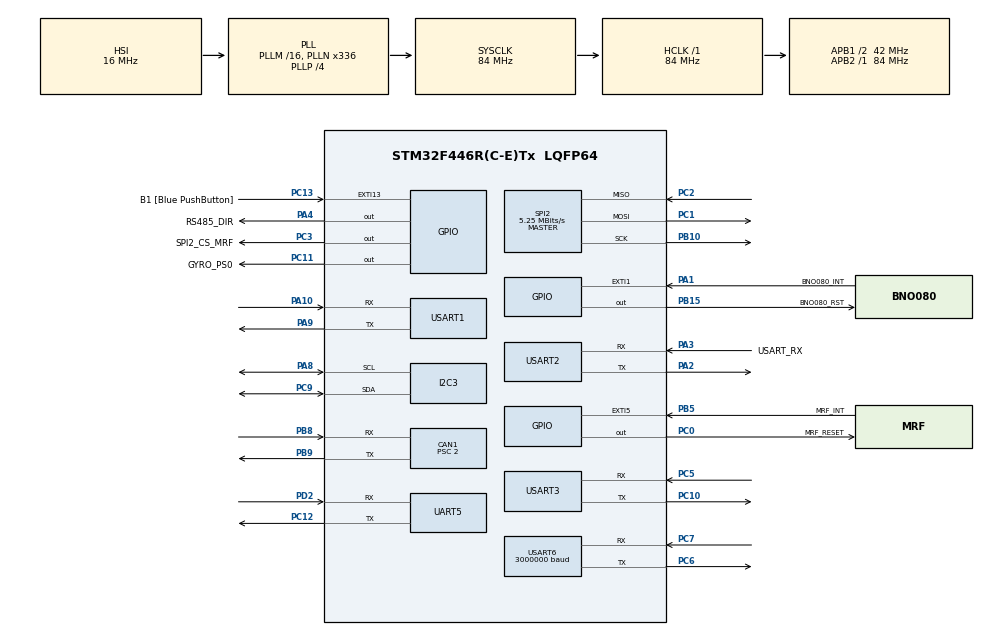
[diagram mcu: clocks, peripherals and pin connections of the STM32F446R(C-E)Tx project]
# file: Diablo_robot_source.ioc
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CAN1.BS1=CAN_BS1_12TQ
CAN1.BS2=CAN_BS2_8TQ
CAN1.CalculateBaudRate=1000000
CAN1.CalculateTimeBit=1000
CAN1.CalculateTimeQuantum=47.61904761904762
CAN1.Prescaler=2
CAN1.SJW=CAN_SJW_1TQ
Dma.Request0=UART5_RX
Dma.Request1=UART5_TX
Dma.Request2=USART1_RX
Dma.Request3=USART1_TX
Dma.Request4=USART3_TX
Dma.Request5=USART2_RX
Dma.Request6=USART2_TX
Dma.UART5_RX.0.Direction=DMA_PERIPH_TO_MEMORY
Dma.UART5_RX.0.FIFOMode=DMA_FIFOMODE_DISABLE
Dma.UART5_RX.0.Instance=DMA1_Stream0
Dma.UART5_RX.0.MemDataAlignment=DMA_MDATAALIGN_BYTE
Dma.UART5_RX.0.MemInc=DMA_MINC_ENABLE
Dma.UART5_RX.0.Mode=DMA_CIRCULAR
Dma.UART5_RX.0.PeriphDataAlignment=DMA_PDATAALIGN_BYTE
Dma.UART5_RX.0.PeriphInc=DMA_PINC_DISABLE
Dma.UART5_RX.0.Priority=DMA_PRIORITY_LOW
Dma.UART5_TX.1.Direction=DMA_MEMORY_TO_PERIPH
Dma.UART5_TX.1.FIFOMode=DMA_FIFOMODE_DISABLE
Dma.UART5_TX.1.Instance=DMA1_Stream7
Dma.UART5_TX.1.MemDataAlignment=DMA_MDATAALIGN_BYTE
Dma.UART5_TX.1.MemInc=DMA_MINC_ENABLE
Dma.UART5_TX.1.Mode=DMA_NORMAL
Dma.UART5_TX.1.PeriphDataAlignment=DMA_PDATAALIGN_BYTE
Dma.UART5_TX.1.PeriphInc=DMA_PINC_DISABLE
Dma.UART5_TX.1.Priority=DMA_PRIORITY_LOW
Dma.USART1_RX.2.Direction=DMA_PERIPH_TO_MEMORY
Dma.USART1_RX.2.FIFOMode=DMA_FIFOMODE_DISABLE
Dma.USART1_RX.2.Instance=DMA2_Stream2
Dma.USART1_RX.2.MemDataAlignment=DMA_MDATAALIGN_BYTE
Dma.USART1_RX.2.MemInc=DMA_MINC_ENABLE
Dma.USART1_RX.2.Mode=DMA_CIRCULAR
Dma.USART1_RX.2.PeriphDataAlignment=DMA_PDATAALIGN_BYTE
Dma.USART1_RX.2.PeriphInc=DMA_PINC_DISABLE
Dma.USART1_RX.2.Priority=DMA_PRIORITY_LOW
Dma.USART1_TX.3.Direction=DMA_MEMORY_TO_PERIPH
Dma.USART1_TX.3.FIFOMode=DMA_FIFOMODE_DISABLE
Dma.USART1_TX.3.Instance=DMA2_Stream7
Dma.USART1_TX.3.MemDataAlignment=DMA_MDATAALIGN_BYTE
Dma.USART1_TX.3.MemInc=DMA_MINC_ENABLE
Dma.USART1_TX.3.Mode=DMA_NORMAL
Dma.USART1_TX.3.PeriphDataAlignment=DMA_PDATAALIGN_BYTE
Dma.USART1_TX.3.PeriphInc=DMA_PINC_DISABLE
Dma.USART1_TX.3.Priority=DMA_PRIORITY_LOW
Dma.USART2_RX.5.Direction=DMA_PERIPH_TO_MEMORY
Dma.USART2_RX.5.FIFOMode=DMA_FIFOMODE_DISABLE
Dma.USART2_RX.5.Instance=DMA1_Stream5
Dma.USART2_RX.5.MemDataAlignment=DMA_MDATAALIGN_BYTE
Dma.USART2_RX.5.MemInc=DMA_MINC_ENABLE
Dma.USART2_RX.5.Mode=DMA_NORMAL
Dma.USART2_RX.5.PeriphDataAlignment=DMA_PDATAALIGN_BYTE
Dma.USART2_RX.5.PeriphInc=DMA_PINC_DISABLE
Dma.USART2_RX.5.Priority=DMA_PRIORITY_LOW
Dma.USART2_TX.6.Direction=DMA_MEMORY_TO_PERIPH
Dma.USART2_TX.6.FIFOMode=DMA_FIFOMODE_DISABLE
Dma.USART2_TX.6.Instance=DMA1_Stream6
Dma.USART2_TX.6.MemDataAlignment=DMA_MDATAALIGN_BYTE
Dma.USART2_TX.6.MemInc=DMA_MINC_ENABLE
Dma.USART2_TX.6.Mode=DMA_NORMAL
Dma.USART2_TX.6.PeriphDataAlignment=DMA_PDATAALIGN_BYTE
Dma.USART2_TX.6.PeriphInc=DMA_PINC_DISABLE
Dma.USART2_TX.6.Priority=DMA_PRIORITY_LOW
Dma.USART3_TX.4.Direction=DMA_MEMORY_TO_PERIPH
Dma.USART3_TX.4.FIFOMode=DMA_FIFOMODE_DISABLE
Dma.USART3_TX.4.Instance=DMA1_Stream3
Dma.USART3_TX.4.MemDataAlignment=DMA_MDATAALIGN_BYTE
Dma.USART3_TX.4.MemInc=DMA_MINC_ENABLE
Dma.USART3_TX.4.Mode=DMA_NORMAL
Dma.USART3_TX.4.PeriphDataAlignment=DMA_PDATAALIGN_BYTE
Dma.USART3_TX.4.PeriphInc=DMA_PINC_DISABLE
Dma.USART3_TX.4.Priority=DMA_PRIORITY_LOW
I2C3.I2C_Mode=I2C_Fast
Mcu.Family=STM32F4
Mcu.Name=STM32F446R(C-E)Tx
Mcu.Package=LQFP64
NVIC.CAN1_RX0_IRQn=true\:0\:0\:false\:false\:true\:true\:true\:true
NVIC.DMA1_Stream0_IRQn=true\:0\:0\:false\:false\:true\:false\:true\:true
NVIC.DMA1_Stream3_IRQn=true\:0\:0\:false\:false\:true\:false\:true\:true
NVIC.DMA1_Stream5_IRQn=true\:0\:0\:false\:false\:true\:false\:true\:true
NVIC.DMA1_Stream6_IRQn=true\:0\:0\:false\:false\:true\:false\:true\:true
NVIC.DMA1_Stream7_IRQn=true\:0\:0\:false\:false\:true\:false\:true\:true
NVIC.DMA2_Stream2_IRQn=true\:0\:0\:false\:false\:true\:false\:true\:true
NVIC.DMA2_Stream7_IRQn=true\:0\:0\:false\:false\:true\:false\:true\:true
NVIC.EXTI15_10_IRQn=true\:0\:0\:false\:false\:true\:true\:true\:true
NVIC.EXTI1_IRQn=true\:0\:0\:false\:false\:true\:true\:true\:true
NVIC.EXTI9_5_IRQn=true\:0\:0\:false\:false\:true\:true\:true\:true
NVIC.PriorityGroup=NVIC_PRIORITYGROUP_0
NVIC.TIM2_IRQn=true\:0\:0\:false\:false\:true\:true\:true\:true
NVIC.TIM3_IRQn=true\:0\:0\:false\:false\:true\:true\:true\:true
NVIC.TIM4_IRQn=true\:0\:0\:false\:false\:true\:true\:true\:true
NVIC.UART5_IRQn=true\:0\:0\:false\:false\:true\:true\:true\:true
NVIC.USART1_IRQn=true\:0\:0\:false\:false\:true\:true\:true\:true
NVIC.USART2_IRQn=true\:0\:0\:false\:false\:true\:true\:true\:true
NVIC.USART3_IRQn=true\:0\:0\:false\:false\:true\:true\:true\:true
NVIC.USART6_IRQn=true\:0\:0\:false\:false\:true\:true\:true\:true
PA1.GPIO_Label=BNO080_INT
PA1.GPIO_ModeDefaultEXTI=GPIO_MODE_IT_FALLING
PA1.GPIO_PuPd=GPIO_PULLUP
PA1.Signal=GPXTI1
PA10.Mode=Asynchronous
PA10.Signal=USART1_RX
PA13.GPIO_Label=TMS
PA13.Mode=Serial_Wire
PA13.Signal=SYS_JTMS-SWDIO
PA14.GPIO_Label=TCK
PA14.Mode=Serial_Wire
PA14.Signal=SYS_JTCK-SWCLK
PA2.Mode=Asynchronous
PA2.Signal=USART2_TX
PA3.GPIO_Label=USART_RX
PA3.Mode=Asynchronous
PA3.Signal=USART2_RX
PA4.GPIO_Label=RS485_DIR
PA4.Signal=GPIO_Output
PA8.Mode=I2C
PA8.Signal=I2C3_SCL
PA9.Mode=Asynchronous
PA9.Signal=USART1_TX
PB10.Mode=Full_Duplex_Master
PB10.Signal=SPI2_SCK
PB15.GPIO_Label=BNO080_RST
PB15.Signal=GPIO_Output
PB5.GPIO_Label=MRF_INT
PB5.Signal=GPXTI5
PB8.Mode=CAN_Activate
PB8.Signal=CAN1_RX
PB9.Mode=CAN_Activate
PB9.Signal=CAN1_TX
PC0.GPIO_Label=MRF_RESET
PC0.Signal=GPIO_Output
PC1.Mode=Full_Duplex_Master
PC1.Signal=SPI2_MOSI
PC10.Mode=Asynchronous
PC10.Signal=USART3_TX
PC11.GPIO_Label=GYRO_PS0
PC11.PinState=GPIO_PIN_SET
PC11.Signal=GPIO_Output
PC12.Mode=Asynchronous
PC12.Signal=UART5_TX
PC13.GPIO_Label=B1 [Blue PushButton]
PC13.GPIO_ModeDefaultEXTI=GPIO_MODE_IT_FALLING
PC13.Signal=GPXTI13
PC2.Mode=Full_Duplex_Master
PC2.Signal=SPI2_MISO
PC3.GPIO_Label=SPI2_CS_MRF
PC3.Signal=GPIO_Output
PC5.Mode=Asynchronous
PC5.Signal=USART3_RX
PC6.Mode=Asynchronous
PC6.Signal=USART6_TX
PC7.Mode=Asynchronous
PC7.Signal=USART6_RX
PC9.Mode=I2C
PC9.Signal=I2C3_SDA
PD2.Mode=Asynchronous
PD2.Signal=UART5_RX
PH0-OSC_IN.Mode=HSE-External-Oscillator
PH0-OSC_IN.Signal=RCC_OSC_IN
PH1-OSC_OUT.Mode=HSE-External-Oscillator
PH1-OSC_OUT.Signal=RCC_OSC_OUT
ProjectManager.HeapSize=0x2000
ProjectManager.StackSize=0x4000
ProjectManager.TargetToolchain=STM32CubeIDE
RCC.48MHZClocksFreq_Value=84000000
RCC.AHBFreq_Value=84000000
RCC.APB1CLKDivider=RCC_HCLK_DIV2
RCC.APB1Freq_Value=42000000
RCC.APB1TimFreq_Value=84000000
RCC.APB2Freq_Value=84000000
RCC.APB2TimFreq_Value=84000000
RCC.CortexFreq_Value=84000000
RCC.FLatency-AdvancedSettings=FLASH_LATENCY_2
RCC.HCLKFreq_Value=84000000
RCC.HSE_VALUE=8000000
RCC.HSI_VALUE=16000000
RCC.PLLN=336
RCC.PLLP=RCC_PLLP_DIV4
RCC.SYSCLKFreq_VALUE=84000000
RCC.SYSCLKSource=RCC_SYSCLKSOURCE_PLLCLK
RCC.USBFreq_Value=168000000
RCC.VCOOutputFreq_Value=336000000
SPI2.BaudRatePrescaler=SPI_BAUDRATEPRESCALER_8
SPI2.CalculateBaudRate=5.25 MBits/s
SPI2.Direction=SPI_DIRECTION_2LINES
SPI2.Mode=SPI_MODE_MASTER
SPI2.VirtualType=VM_MASTER
STMicroelectronics.X-CUBE-AI.8.1.0.ActivationBufferSizeList=2836
STMicroelectronics.X-CUBE-AI.8.1.0.ActivationBuffers=pool0
STMicroelectronics.X-CUBE-AI.8.1.0.ActivationNames=pool0
STMicroelectronics.X-CUBE-AI.8.1.0.ActivationSizes=AI_ANN_DATA_ACTIVATION_1_SIZE
STMicroelectronics.X-CUBE-AI.8.1.0.ApplicationCcDeviceJjApplication=ApplicationTemplate
STMicroelectronics.X-CUBE-AI.8.1.0.HeapSize=0x2000
STMicroelectronics.X-CUBE-AI.8.1.0.InternalRamActivationBufferMaxSize=AI_ANN_DATA_ACTIVATIONS_SIZE
STMicroelectronics.X-CUBE-AI.8.1.0.LatestDirectoryUsed-02a6a88e550a600aeb2759edbb2ea6d297313e899456552873ac68f6a92de1a0=E\:\\
STMicroelectronics.X-CUBE-AI.8.1.0.MaximumNumberOfInputLayer=1
STMicroelectronics.X-CUBE-AI.8.1.0.MaximumNumberOfOutputLayer=1
STMicroelectronics.X-CUBE-AI.8.1.0.MaximumSizeOfInputLayer=1
STMicroelectronics.X-CUBE-AI.8.1.0.MaximumSizeOfOutputLayer=1
STMicroelectronics.X-CUBE-AI.8.1.0.ModelActualCompression-02a6a88e550a600aeb2759edbb2ea6d297313e899456552873ac68f6a92de1a0=0.0
STMicroelectronics.X-CUBE-AI.8.1.0.ModelCompression-02a6a88e550a600aeb2759edbb2ea6d297313e899456552873ac68f6a92de1a0=None
STMicroelectronics.X-CUBE-AI.8.1.0.ModelFlashOccupation-02a6a88e550a600aeb2759edbb2ea6d297313e899456552873ac68f6a92de1a0=31762
STMicroelectronics.X-CUBE-AI.8.1.0.ModelHashList=02a6a88e550a600aeb2759edbb2ea6d297313e899456552873ac68f6a92de1a0
STMicroelectronics.X-CUBE-AI.8.1.0.ModelKind-02a6a88e550a600aeb2759edbb2ea6d297313e899456552873ac68f6a92de1a0=ONNX
STMicroelectronics.X-CUBE-AI.8.1.0.ModelMacc-02a6a88e550a600aeb2759edbb2ea6d297313e899456552873ac68f6a92de1a0=6392
STMicroelectronics.X-CUBE-AI.8.1.0.ModelName-02a6a88e550a600aeb2759edbb2ea6d297313e899456552873ac68f6a92de1a0=ann
STMicroelectronics.X-CUBE-AI.8.1.0.ModelNameList=ann
STMicroelectronics.X-CUBE-AI.8.1.0.ModelRamOccupation-02a6a88e550a600aeb2759edbb2ea6d297313e899456552873ac68f6a92de1a0=2836
STMicroelectronics.X-CUBE-AI.8.1.0.ModelStructureFile-02a6a88e550a600aeb2759edbb2ea6d297313e899456552873ac68f6a92de1a0=E\:\\policy.onnx
STMicroelectronics.X-CUBE-AI.8.1.0.ModelType-02a6a88e550a600aeb2759edbb2ea6d297313e899456552873ac68f6a92de1a0=Saved model
STMicroelectronics.X-CUBE-AI.8.1.0.ReadyForCodeGeneration=true
STMicroelectronics.X-CUBE-AI.8.1.0.StackSize=0x4000
STMicroelectronics.X-CUBE-AI.8.1.0.WorkingBufferStartAddrList=0xFFFFFFFF
STMicroelectronics.X-CUBE-AI.8.1.0.XAaCUBEAaAICcArtificialOoIntelligenceJjCore=true
STMicroelectronics.X-CUBE-AI.8.1.0.copyWeightToRam=false
STMicroelectronics.X-CUBE-AI.8.1.0.customLayerConfigEnabled=false
STMicroelectronics.X-CUBE-AI.8.1.0.noOnnxIoTranspose=false
STMicroelectronics.X-CUBE-AI.8.1.0.useInputAllocation=true
STMicroelectronics.X-CUBE-AI.8.1.0.useOutputAllocation=true
TIM2.Period=100000-1
TIM2.Prescaler=84-1
TIM3.AutoReloadPreload=TIM_AUTORELOAD_PRELOAD_ENABLE
TIM3.Period=49999
TIM3.Prescaler=167
TIM4.AutoReloadPreload=TIM_AUTORELOAD_PRELOAD_ENABLE
TIM4.Period=59999
TIM4.Prescaler=20
UART5.VirtualMode=Asynchronous
USART1.VirtualMode=VM_ASYNC
USART2.Parity=PARITY_NONE
USART2.VirtualMode=VM_ASYNC
USART2.WordLength=WORDLENGTH_8B
USART3.VirtualMode=VM_ASYNC
USART6.BaudRate=3000000
USART6.VirtualMode=VM_ASYNC
VP_CRC_VS_CRC.Mode=CRC_Activate
VP_STMicroelectronics.X-CUBE-AI_VS_ArtificialOoIntelligenceJjXAaCUBEAaAI_8.1.0.Mode=ArtificialOoIntelligenceJjXAaCUBEAaAI
VP_STMicroelectronics.X-CUBE-AI_VS_DeviceJjApplication_8.1.0.Mode=DeviceJjApplication
VP_TIM2_VS_ClockSourceINT.Mode=Internal
VP_TIM3_VS_ClockSourceINT.Mode=Internal
VP_TIM4_VS_ClockSourceINT.Mode=Internal
board=NUCLEO-F446RE

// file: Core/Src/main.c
/* USER CODE BEGIN Header */
/**
  ******************************************************************************
  * @file           : main.c
  * @brief          : Main program body
  ******************************************************************************
  * @attention
  *
  * Copyright (c) 2022 STMicroelectronics.
  * All rights reserved.
  *
  * This software is licensed under terms that can be found in the LICENSE file
  * in the root directory of this software component.
  * If no LICENSE file comes with this software, it is provided AS-IS.
  *
  ******************************************************************************
  */
/* USER CODE END Header */
#include "main.h"
#include "app_x-cube-ai.h"

/* USER CODE BEGIN Includes */

#include "math.h"
#include "string.h"
#include <stdbool.h>

// Custom headers
#include "cybergear.h"
#include "DDSM115.h"
#include "kinematics.h"
#include "system_init.h"
#include "telemetry.h"
#include "controler.h"
#include "joystick.h"
#include "StartupStrategy.h"
#include "StateEstimator.h"
#include "state_machine.h"
#include "JumpStrategy.h"
#include "bno08x.h"

/* USER CODE END Includes */

/* USER CODE BEGIN PD */

// ESP32 buffer size (ROLL PITCH YAW)
#define PACKET_SIZE 19

// Set to 1 to re-enable the UART2 debug telemetry print to the ESP32.
// Disabled by default to save loop time for the 15ms ANN/DDSM115 update.
#define ENABLE_UART2_DEBUG_TELEMETRY 0

/* USER CODE END PD */

CAN_HandleTypeDef hcan1;

CRC_HandleTypeDef hcrc;

I2C_HandleTypeDef hi2c3;

SPI_HandleTypeDef hspi2;

TIM_HandleTypeDef htim2;
TIM_HandleTypeDef htim3;
TIM_HandleTypeDef htim4;

UART_HandleTypeDef huart5;
UART_HandleTypeDef huart1;
UART_HandleTypeDef huart2;
UART_HandleTypeDef huart3;
UART_HandleTypeDef huart6;
DMA_HandleTypeDef hdma_uart5_rx;
DMA_HandleTypeDef hdma_uart5_tx;
DMA_HandleTypeDef hdma_usart1_rx;
DMA_HandleTypeDef hdma_usart1_tx;
DMA_HandleTypeDef hdma_usart2_rx;
DMA_HandleTypeDef hdma_usart2_tx;
DMA_HandleTypeDef hdma_usart3_tx;

/* USER CODE BEGIN PV */

// Transcieve header
CAN_TxHeaderTypeDef pTxHeader;

// Receive header
CAN_RxHeaderTypeDef pRxHeader;

// Filter for receiving all extended frames
CAN_FilterTypeDef sFilterConfig;

uint8_t RxSingleByte;
uint16_t angle_u;
int16_t velocityDDSM_RPM = 0;

uint8_t RS485_RxBuffer[RS485_BUFFER_SIZE];

// ===== AI network globals =====
STAI_NETWORK_CONTEXT_DECLARE(ann_network_context, STAI_NETWORK_CONTEXT_SIZE)
STAI_ALIGNED(32) static uint8_t ann_activations[STAI_NETWORK_ACTIVATION_1_SIZE_BYTES];
STAI_ALIGNED(4) static float ann_in_data[STAI_NETWORK_IN_1_SIZE];
STAI_ALIGNED(4) static float ann_out_data[STAI_NETWORK_OUT_1_SIZE];
static stai_ptr ann_input[STAI_NETWORK_IN_NUM] = { (stai_ptr)ann_in_data };
static stai_ptr ann_output[STAI_NETWORK_OUT_NUM] = { (stai_ptr)ann_out_data };

static float prev_action_left  = 0.0f;
static float prev_action_right = 0.0f;

#define WHEEL_POS_SIGN_LEFT        (-1.0f)
#define WHEEL_POS_SIGN_RIGHT       (+1.0f)
#define WHEEL_VEL_SIGN_LEFT        (-1.0f)
#define WHEEL_VEL_SIGN_RIGHT       (+1.0f)

#define PITCH_SIGN                 (+1.0f)
#define PITCH_RATE_SIGN            (+1.0f)
#define YAW_SIGN                   (-1.0f)
#define YAW_RATE_SIGN              (-1.0f)

// ===== BNO08x mount mapping (replaces the removed ESP32 IMU bridge) =====
// The four *_esp32 globals below used to be filled from a 25-byte UART1 packet
// sent by an ESP32 that carried the BNO. That ESP32 is gone; the BNO08x is now
// wired straight to I2C3 and IMU_UpdateFromBNO() fills the same globals, so the
// PITCH_/YAW_ signs above and everything downstream (ANN_Run, MET_Update,
// LOG_Update, isFallen) stay exactly as they were for the ERK measurements.
//
// The mounting changed along with the wiring. It was NOT measured off the
// hardware; it is inferred from the recorded runs, and everything below follows
// from that inference: the old and new sensor frames are related by a
// 180-degree rotation about the chassis Z (up) axis, i.e. sensor X and Y flip
// and Z is unchanged. It is the only axis-aligned rotation that fits both the
// measured pitch evidence and a sensor whose Z still points up. That is what
// makes every mapping below a straight 1:1 assignment rather than a negation:
//
//   theta      old ESP32 euler "roll" = +rot about old sensor X.
//              new body_pitch_rad = atan2(g_y,-g_z) = -rot about new sensor X.
//              New X is anti-parallel to old X, so the two cancel and the new
//              value carries the same sign as the old one for the same lean.
//              Confirmed against the recorded runs: d(action)/d(theta) is
//              positive in both meritve_erk/ (+1.4..+4.6) and the current
//              firmware's captures (+2.1..+2.6), i.e. the policy's pitch
//              feedback has the same sign under both mountings.
//   theta_dot  body_pitch_rate_rad_s is -bno_gx, and -(new X) = +(old X), so it
//              equals the old gx_esp32. Verified as the true derivative of
//              theta in both data sets (slope +1.00, corr +0.97 on a 200 ms
//              baseline), so the theta/theta_dot pair stays self-consistent.
//   yaw,       Both come from the BNO's gravity-aligned world frame (quaternion
//   yaw_rate   yaw, and the gyro vector rotated into world Z - see
//              IMU_UpdateFromBNO). YAW_RATE_SIGN below still applies. Note the
//              newer TwoWheeledRobotEmbeddedCore firmware instead drops that
//              -1 and crosses the two wheel destinations at the actuator; do
//              NOT copy that here - this project has no crossing, so it needs
//              the sign. Yaw itself is only ever used as wrap_pi(yaw - yaw_ref)
//              against a reference latched at run start, so the constant
//              heading offset between the two mountings cancels.
//
// YAW_MOUNT_SIGN is applied to the yaw angle and the yaw rate together, so the
// pair stays coherent whichever way it is set (yaw_rate_obs = d(yaw_err)/dt
// either way). With a coherent pair the whole yaw loop reduces to one condition.
// Fitting all 8 obs against the differential action across the four ERK runs
// gives the network's yaw law as D = aL-aR = -2.0*obs4 - 2.5*obs5 (R2 0.96..0.999,
// both signs consistent across runs) - a PD on heading error. Closing the loop:
//
//     yaw_err_ddot = (YAW_MOUNT_SIGN * k / J) * (0.637*yaw_err + 0.625*yaw_err_dot)
//
// where k = +/-1 is the physical yaw actuation polarity. Stable iff
//
//     YAW_MOUNT_SIGN * k < 0
//
// Two hardware runs on 2026-09-07 pinned k down. Both spun up, so both remaining
// unknowns are now resolved:
//   -1.0f  ran away  ->  k = -1  ->  +1.0f is the stable setting.
// k = -1 means this chassis' physical yaw response is inverted relative to the
// ERK era, which is the same finding that made TwoWheeledRobotEmbeddedCore cross
// its two wheel destinations at the actuator. Crossing there and flipping the
// sign here are equivalent for the yaw loop, and neither touches forward drive
// (ddsm[0]-ddsm[1] = aL+aR either way). Pitch is independent of all of this and
// was already confirmed correct on hardware - see the theta entry above.
#define YAW_MOUNT_SIGN             (+1.0f)

#define DDSM_CURRENT_SIGN_LEFT     (+1.0f)
#define DDSM_CURRENT_SIGN_RIGHT    (-1.0f)
#define STM32_TEST_CURRENT_LIMIT_A (0.5f)

// ===== Bench metrics for STM Studio (metrics_per_run_template.csv columns) =====
// All "MET_" variables are updated once per 15ms control tick (see MET_Update()).
// From STM Studio: write MET_reset = 1 to zero the accumulators and start timing a
// new run; the firmware clears it back to 0 automatically on the next tick.
// Read the MET_ values off the STM Studio watch after the run/scenario finishes
// and copy them into the matching CSV columns (initial_theta_deg, max_abs_theta_deg,
// rms_theta_deg, rms_I_A, t_rec_s, x_final_m).
#define MET_RAD2DEG                (180.0f / 3.14159265358979323846f)
#define MET_SAMPLE_DT_S            (0.015f)  // 15ms TIM4 tick
#define MET_THETA_DISTURBED_DEG    (2.0f)    // |theta| above this counts as "disturbed"
#define MET_THETA_SETTLED_DEG      (1.5f)    // |theta| must stay below this to count as recovered
#define MET_SETTLE_HOLD_S          (0.3f)    // how long it must stay settled before t_rec_s freezes

volatile uint8_t MET_reset             = 0;     // write 1 to start a new run
volatile float   MET_theta_deg         = 0.0f;  // instantaneous pitch (deg), for live viewing
volatile float   MET_theta_init_deg    = 0.0f;  // -> initial_theta_deg
volatile float   MET_theta_max_abs_deg = 0.0f;  // -> max_abs_theta_deg
volatile float   MET_theta_rms_deg     = 0.0f;  // -> rms_theta_deg
volatile float   MET_I_rms_A           = 0.0f;  // -> rms_I_A
volatile float   MET_t_rec_s           = 0.0f;  // -> t_rec_s
volatile float   MET_x_final_m         = 0.0f;  // -> x_final_m (keeps updating; last value before you stop = final)
volatile float   MET_run_time_s        = 0.0f;  // elapsed time since MET_reset (context, not a CSV column)

// ===== Per-tick telemetry for STM Studio (timeseries_log_template.csv columns) =====
// All "LOG_" variables are updated once per 15ms control tick (see LOG_Update()).
// Start the STM Studio recording the instant you let go of the robot (or, for
// undisturbed_balance, whenever you want t=0 to be) - that recorded sample becomes
// t_s = 0, and LOG_theta_deg from that first sample is your initial_theta_deg.
// obs_0..obs_7 are the exact 8 floats fed to the network (ann_in_data, normalized) -
// adjust LOG_Update() if your training env logged obs in a different order/units.
// action_L/R are the network's raw output (pre sign-flip, pre safety clamp);
// I_L/R_cmd_A and I_L/R_meas_A are both the same commanded current actually sent to
// the DDSM115 (post sign-flip and clamping) - there's no separate current feedback
// from the drive, so "measured" just mirrors "commanded".
volatile float   LOG_theta_deg      = 0.0f;  // instantaneous pitch (deg); first recorded sample -> initial_theta_deg
volatile float   LOG_obs[8]         = {0};   // -> obs_0..obs_7
volatile float   LOG_action_L       = 0.0f;  // -> action_L (raw network output)
volatile float   LOG_action_R       = 0.0f;  // -> action_R (raw network output)
volatile float   LOG_I_L_cmd_A      = 0.0f;  // -> I_L_cmd_A
volatile float   LOG_I_R_cmd_A      = 0.0f;  // -> I_R_cmd_A
volatile float   LOG_I_L_meas_A     = 0.0f;  // -> I_L_meas_A
volatile float   LOG_I_R_meas_A     = 0.0f;  // -> I_R_meas_A

/* USER CODE END PV */

void SystemClock_Config(void);
static void MX_GPIO_Init(void);
static void MX_DMA_Init(void);
static void MX_CAN1_Init(void);
static void MX_TIM3_Init(void);
static void MX_TIM4_Init(void);
static void MX_UART5_Init(void);
static void MX_SPI2_Init(void);
static void MX_I2C3_Init(void);
static void MX_USART6_UART_Init(void);
static void MX_USART1_UART_Init(void);
static void MX_USART3_UART_Init(void);
static void MX_USART2_UART_Init(void);
static void MX_TIM2_Init(void);
static void MX_CRC_Init(void);
/* USER CODE BEGIN PFP */
void HAL_CAN_RxFifo0MsgPendingCallback(CAN_HandleTypeDef *hcan);
void HAL_UART_RxCpltCallback(UART_HandleTypeDef *huart);
uint16_t getDMACurrentIndex(void);
volatile uint16_t rxReadIndex = 0;       // Your software read pointer

#define BNO080_PACKET_SIZE 25  // 1 SOF + 6×4-byte floats
#define UART1_RX_BUFFER_SIZE 128
static uint8_t  uart1RxBuffer[UART1_RX_BUFFER_SIZE];

#define UART2_RX_BUFFER_SIZE 10
static uint8_t uart2RxBuffer[UART2_RX_BUFFER_SIZE];

float ddsm_NN_current_command[2] = {0};

char NN_buffer[80] = {0};

void ANN_Init(void);
void ANN_Run(void);
static float clamp_float(float value, float min_value, float max_value);
static float wrap_pi(float angle_rad);
static void MET_Update(void);
static void LOG_Update(void);
static void IMU_UpdateFromBNO(void);

/* USER CODE END PFP */

/* USER CODE BEGIN 0 */
uint8_t sendUart2Data = 0;
/* USER CODE END 0 */

int main(void)
{

  /* MCU Configuration--------------------------------------------------------*/

  /* Reset of all peripherals, Initializes the Flash interface and the Systick. */
  HAL_Init();

  /* Configure the system clock */
  SystemClock_Config();

  /* USER CODE BEGIN SysInit */
  /*for (int i = 0; i < 10; i++) {
	  // Right after MX_GPIO_Init();
	  HAL_GPIO_TogglePin(GPIOA, LED_BUILTIN_Pin);
	  HAL_Delay(200);
	  HAL_GPIO_TogglePin(GPIOA, LED_BUILTIN_Pin);
  }*/
  /* USER CODE END SysInit */

  /* Initialize all configured peripherals */
  MX_GPIO_Init();
  MX_DMA_Init();
  MX_CAN1_Init();
  MX_TIM3_Init();
  MX_TIM4_Init();
  MX_UART5_Init();
  MX_SPI2_Init();
  MX_I2C3_Init();
  MX_USART6_UART_Init();
  MX_USART1_UART_Init();
  MX_USART3_UART_Init();
  MX_USART2_UART_Init();
  MX_TIM2_Init();
  MX_CRC_Init();
  //MX_X_CUBE_AI_Init();
  /* USER CODE BEGIN 2 */

  ANN_Init();

  /*char boot[60];
  sprintf(boot, "BOOT OK - NN init done\r\n");
  HAL_UART_Transmit(&huart3, (uint8_t*)boot, strlen(boot), 100);
  HAL_Delay(100);*/

  // USART1 reception intentionally NOT started: it only ever carried the ESP32
  // IMU packet, and the BNO08x is now read directly over I2C3 (see
  // IMU_UpdateFromBNO). Leaving it disarmed means the parser below can never
  // fire and overwrite the *_esp32 globals with stale/garbage frames.
  // HAL_UARTEx_ReceiveToIdle_IT(&huart1,
  //                            uart1RxBuffer,
  //                            UART1_RX_BUFFER_SIZE);

  // Enable UART DMA for uart2
  HAL_UART_Receive_DMA(&huart2, uart2RxBuffer, UART2_RX_BUFFER_SIZE);

  // Enable UART DMA for uart4
  HAL_UARTEx_ReceiveToIdle_IT(&huart5, RS485_RxBuffer, RS485_BUFFER_SIZE);

  // ------ PRECISE SAMPLE TIME MEASUREMENTS ------

  // Enable TRC (Trace control) - needed to use DWT
  CoreDebug->DEMCR |= CoreDebug_DEMCR_TRCENA_Msk;

  // Reset the cycle counter
  DWT->CYCCNT = 0;

  // Enable the cycle counter
  DWT->CTRL |= DWT_CTRL_CYCCNTENA_Msk;

  //------------------------------------------------

  // BNO08x on I2C3 (PA8/PC9), INT on PA1, RST on PB15 - all already configured
  // by MX_GPIO_Init/MX_I2C3_Init. Must come after the DWT block above: the SH-2
  // HAL glue timestamps its reads from DWT->CYCCNT. Blocks ~0.5 s while the
  // sensor resets and the three reports are enabled, which is fine here (still
  // before the TIM4 control tick starts).
  BNO08x_Init(&hi2c3, BNO080_INT_Pin);

// SEND QUERY TO DDSM115
  uint8_t cmd[10] = {0};
  cmd[0] = 0xAA;  // Motor ID
  cmd[1] = 0x64;
  cmd[2] = 0x00;  // High byte
  cmd[3] = 0x00;  // Low byte
  cmd[4] = 0x00;
  cmd[5] = 0x00;
  cmd[6] = 0x00;
  cmd[7] = 0x00;
  cmd[8] = 0x00;
  cmd[9] = compute_crc8(cmd, 9);
  // Set GPIO pin to transmit mode

  HAL_GPIO_WritePin(RS485_DIR_GPIO_Port, RS485_DIR_Pin, GPIO_PIN_SET);
  HAL_UART_Transmit(&huart5, cmd, 10, HAL_MAX_DELAY);
  HAL_Delay(10);  // Allow time for the command to be processed
  // Set GPIO pin to receive mode
  HAL_GPIO_WritePin(RS485_DIR_GPIO_Port, RS485_DIR_Pin, GPIO_PIN_RESET);

  // CAN
  // 1) Configure the CAN filter to accept *all* extended frames
  CAN_FilterTypeDef sFilterConfig;
  sFilterConfig.FilterBank = 0;
  sFilterConfig.FilterMode = CAN_FILTERMODE_IDMASK;
  sFilterConfig.FilterScale = CAN_FILTERSCALE_32BIT;
  sFilterConfig.FilterIdHigh = 0x0000;
  sFilterConfig.FilterIdLow  = 0x0000;
  sFilterConfig.FilterMaskIdHigh = 0x0000;
  sFilterConfig.FilterMaskIdLow  = 0x0000;
  sFilterConfig.FilterFIFOAssignment = CAN_FILTER_FIFO0;
  sFilterConfig.FilterActivation = ENABLE;
  sFilterConfig.SlaveStartFilterBank = 14;
  HAL_CAN_ConfigFilter(&hcan1, &sFilterConfig);

  // 2) Start CAN
  HAL_CAN_Start(&hcan1);

  // 3) Optionally enable Rx interrupt
  HAL_CAN_ActivateNotification(&hcan1, CAN_IT_RX_FIFO0_MSG_PENDING);

  HAL_NVIC_SetPriority(CAN1_RX0_IRQn, 0, 0);
  HAL_NVIC_EnableIRQ(CAN1_RX0_IRQn);

  	  // HAL delay to allow the system to stabilize
  	  HAL_Delay(3000);

  	  System_Init();

  	init_leg_state(&leg_state_rf);
  	init_leg_state(&leg_state_lf);
  	init_leg_state(&leg_state_rb);
  	init_leg_state(&leg_state_lb);

  	// Testing of inverse kinematics

  	//start TIM2 for USART2 data transfer
  		HAL_TIM_Base_Start_IT(&htim2);
		  // Enable Timer 3 interupt
		  HAL_TIM_Base_Start_IT(&htim3);
		  // Enable Timer 4 interupt
		  HAL_TIM_Base_Start_IT(&htim4);

		  // 6) (Re-)enable the line just in case
		  HAL_NVIC_EnableIRQ(EXTI9_5_IRQn);

		  HAL_UART_Receive_IT(&huart3, &uart3_controller_byte, 1);  // Start receiving

  /* USER CODE END 2 */

  /* Infinite loop */
  /* USER CODE BEGIN WHILE */

  while (1)
  {

	  // ----- MAIN CONTROL LOOP -----
	  // Seperated by flags for auxiliary tasks and a state machine

	 // Service the BNO08x (no-ops unless its INT pin has signaled new data) and
	 // refresh the *_esp32 globals every pass, before any consumer below reads
	 // them. Replaces the ESP32 UART1 packet that used to do this in an ISR.
	 BNO08x_Service();
	 IMU_UpdateFromBNO();

	 if (isCANReady) {
		 isCANReady = false;
		 }

	 if (uart3_controller_packet_ready) {
		 process_joystick_input();
		 uart3_controller_packet_ready = 0;
	 }

	 if (isCYBERGEARReady){

		 if (isFallen())
		 {
			 if (startPressed == 1) isStartupStrategy = true;
		 }else{
			 if (xPressed == 1) isJumpStrategy = true;
		 }

		 if(isStartupStrategy)
		 {
			 startup_strategy_control();
		 }

		 if(isFallen()){
			 DDSM115setCurrent(0x10, 0);
			 HAL_Delay(2);
			 DDSM115setCurrent(0x11, 0);

		 }

		 if(isJumpStrategy)
		 {
			 jump_strategy_control();
		 }

		 	// ROBOT IS STANDING AND OPERATIONAL
		    if (!isFallen()) {
		    	if(isSTATIC){

		    	posture_controler();

		    	MOTOR_CG_LF.desired_angle = 0.0f;
		    	MOTOR_CG_LB.desired_angle = -0.0f;
		    	MOTOR_CG_RF.desired_angle = 0.0f;
		    	MOTOR_CG_RB.desired_angle = -0.0f;

		    	Motor_SendMITCommand(&MOTOR_CG_LF);
		    	Motor_SendMITCommand(&MOTOR_CG_LB);
		    	HAL_Delay(5);
		    	Motor_SendMITCommand(&MOTOR_CG_RF);
		    	Motor_SendMITCommand(&MOTOR_CG_RB);

				 isCYBERGEARReady = false;

		    	}
		    	// THE ROBOT IS IN LOCOMOTION STATE
		    	else if(isLOCOMOTION){
		    		// For now the same thing happens as in static

			    	posture_controler();

			    	Motor_SendMITCommand(&MOTOR_CG_LF);
			    	Motor_SendMITCommand(&MOTOR_CG_LB);
			    	HAL_Delay(5);
			    	Motor_SendMITCommand(&MOTOR_CG_RF);
			    	Motor_SendMITCommand(&MOTOR_CG_RB);

					 isCYBERGEARReady = false;
		    	}

		    }
		    else{

		   	 isCYBERGEARReady = false;

		    }
	 }

	/* if (sendUart2Data){

		 sprintf(NN_buffer, "%d%d%.2f%.2f%.2f%.2f%.2f%.2f%.2f\r\n",
				 0xAA, 0x55, pitch_esp32, roll_esp32, gx_esp32, gy_esp32, gz_esp32, DDSM115MotorList[0].x_dot, DDSM115MotorList[1].x_dot);
		 sendUart2Data = 0;
		 HAL_UART_Transmit_DMA(&huart2, (uint8_t*)NN_buffer, strlen(NN_buffer));

		 if(!isFallen() || isStartupStrategy){

		 // calculate_cascaded_motor_currents(desired_v_left,desired_v_right, &current_motor1_out, &current_motor2_out, &total_force_out);

		 //current_motor1_out = 0.0f;
		 //current_motor2_out = 0.0f;

		 DDSM115setCurrent(0x11, -1* ddsm_NN_current_command[0]);
		 HAL_Delay(2);
		 DDSM115setCurrent(0x10, -1* ddsm_NN_current_command[1]);
		 }
		 else{}

		 isDDSM115Ready = false;
	 }*/

	 //ANN UPDATED SENDING FUNCTION
	 // Now gated on the 15ms TIM4 tick (isDDSM115Ready) instead of the 100ms
	 // TIM2 tick (sendUart2Data), so the policy and the DDSM115 current
	 // commands run at ~66.7Hz instead of 10Hz.
	 if (isDDSM115Ready) {
	     isDDSM115Ready = false;

	     // Run policy locally
	     ANN_Run();

	     if (!isFallen() || isStartupStrategy) {
	         DDSM115setCurrent(0x11, 1 * ddsm_NN_current_command[0]);
	         HAL_Delay(5);
	         DDSM115setCurrent(0x10, 1 * ddsm_NN_current_command[1]);
	     }

	     // Bench metrics/telemetry for STM Studio (see MET_/LOG_ globals above), same 15ms tick.
	     MET_Update();
	     LOG_Update();
	 }

	 // Debug telemetry to ESP32, on the slower 100ms tick so UART2/DMA
	 // isn't loaded at the full 66.7Hz control rate.
	 // Disabled for now (ENABLE_UART2_DEBUG_TELEMETRY == 0) to free up loop
	 // time for the faster ANN/DDSM115 update above.
#if ENABLE_UART2_DEBUG_TELEMETRY
	 if (sendUart2Data) {
	     sendUart2Data = 0;

	     sprintf(NN_buffer, "%d%d %.2f %.2f %.2f %.2f %.2f %.2f %.2f | NN: %.3f %.3f\r\n",
	             0xAA, 0x55, pitch_esp32, roll_esp32, gx_esp32, gy_esp32, gz_esp32,
	             DDSM115MotorList[0].x_dot, DDSM115MotorList[1].x_dot,
	             ann_out_data[0], ann_out_data[1]);
	     HAL_UART_Transmit_DMA(&huart2, (uint8_t*)NN_buffer, strlen(NN_buffer));
	 }
#else
	 sendUart2Data = 0;
#endif

	 if (isTELEMETRYReady){
		 Send_Telemetry(&huart3);
	 }

    /* USER CODE END WHILE */

  //MX_X_CUBE_AI_Process();
  }
}

void SystemClock_Config(void)
{
  RCC_OscInitTypeDef RCC_OscInitStruct = {0};
  RCC_ClkInitTypeDef RCC_ClkInitStruct = {0};

  /** Configure the main internal regulator output voltage
  */
  __HAL_RCC_PWR_CLK_ENABLE();
  __HAL_PWR_VOLTAGESCALING_CONFIG(PWR_REGULATOR_VOLTAGE_SCALE3);

  /** Initializes the RCC Oscillators according to the specified parameters
  * in the RCC_OscInitTypeDef structure.
  */
  RCC_OscInitStruct.OscillatorType = RCC_OSCILLATORTYPE_HSI;
  RCC_OscInitStruct.HSIState = RCC_HSI_ON;
  RCC_OscInitStruct.HSICalibrationValue = RCC_HSICALIBRATION_DEFAULT;
  RCC_OscInitStruct.PLL.PLLState = RCC_PLL_ON;
  RCC_OscInitStruct.PLL.PLLSource = RCC_PLLSOURCE_HSI;
  RCC_OscInitStruct.PLL.PLLM = 16;
  RCC_OscInitStruct.PLL.PLLN = 336;
  RCC_OscInitStruct.PLL.PLLP = RCC_PLLP_DIV4;
  RCC_OscInitStruct.PLL.PLLQ = 2;
  RCC_OscInitStruct.PLL.PLLR = 2;
  if (HAL_RCC_OscConfig(&RCC_OscInitStruct) != HAL_OK)
  {
    Error_Handler();
  }

  /** Initializes the CPU, AHB and APB buses clocks
  */
  RCC_ClkInitStruct.ClockType = RCC_CLOCKTYPE_HCLK|RCC_CLOCKTYPE_SYSCLK
                              |RCC_CLOCKTYPE_PCLK1|RCC_CLOCKTYPE_PCLK2;
  RCC_ClkInitStruct.SYSCLKSource = RCC_SYSCLKSOURCE_PLLCLK;
  RCC_ClkInitStruct.AHBCLKDivider = RCC_SYSCLK_DIV1;
  RCC_ClkInitStruct.APB1CLKDivider = RCC_HCLK_DIV2;
  RCC_ClkInitStruct.APB2CLKDivider = RCC_HCLK_DIV1;

  if (HAL_RCC_ClockConfig(&RCC_ClkInitStruct, FLASH_LATENCY_2) != HAL_OK)
  {
    Error_Handler();
  }
}

static void MX_CAN1_Init(void)
{

  hcan1.Instance = CAN1;
  hcan1.Init.Prescaler = 2;
  hcan1.Init.Mode = CAN_MODE_NORMAL;
  hcan1.Init.SyncJumpWidth = CAN_SJW_1TQ;
  hcan1.Init.TimeSeg1 = CAN_BS1_12TQ;
  hcan1.Init.TimeSeg2 = CAN_BS2_8TQ;
  hcan1.Init.TimeTriggeredMode = DISABLE;
  hcan1.Init.AutoBusOff = DISABLE;
  hcan1.Init.AutoWakeUp = DISABLE;
  hcan1.Init.AutoRetransmission = DISABLE;
  hcan1.Init.ReceiveFifoLocked = DISABLE;
  hcan1.Init.TransmitFifoPriority = DISABLE;
  if (HAL_CAN_Init(&hcan1) != HAL_OK)
  {
    Error_Handler();
  }

}

static void MX_CRC_Init(void)
{

  hcrc.Instance = CRC;
  if (HAL_CRC_Init(&hcrc) != HAL_OK)
  {
    Error_Handler();
  }

}

static void MX_I2C3_Init(void)
{

  hi2c3.Instance = I2C3;
  /* 400 kHz: the BNO08x SH-2 stack polls a 4-byte header then the full packet on
     every INT assertion; 100 kHz cannot keep up with the 15 ms control tick. */
  hi2c3.Init.ClockSpeed = 400000;
  hi2c3.Init.DutyCycle = I2C_DUTYCYCLE_2;
  hi2c3.Init.OwnAddress1 = 0;
  hi2c3.Init.AddressingMode = I2C_ADDRESSINGMODE_7BIT;
  hi2c3.Init.DualAddressMode = I2C_DUALADDRESS_DISABLE;
  hi2c3.Init.OwnAddress2 = 0;
  hi2c3.Init.GeneralCallMode = I2C_GENERALCALL_DISABLE;
  hi2c3.Init.NoStretchMode = I2C_NOSTRETCH_DISABLE;
  if (HAL_I2C_Init(&hi2c3) != HAL_OK)
  {
    Error_Handler();
  }

}

static void MX_SPI2_Init(void)
{

  /* SPI2 parameter configuration*/
  hspi2.Instance = SPI2;
  hspi2.Init.Mode = SPI_MODE_MASTER;
  hspi2.Init.Direction = SPI_DIRECTION_2LINES;
  hspi2.Init.DataSize = SPI_DATASIZE_8BIT;
  hspi2.Init.CLKPolarity = SPI_POLARITY_LOW;
  hspi2.Init.CLKPhase = SPI_PHASE_1EDGE;
  hspi2.Init.NSS = SPI_NSS_SOFT;
  hspi2.Init.BaudRatePrescaler = SPI_BAUDRATEPRESCALER_8;
  hspi2.Init.FirstBit = SPI_FIRSTBIT_MSB;
  hspi2.Init.TIMode = SPI_TIMODE_DISABLE;
  hspi2.Init.CRCCalculation = SPI_CRCCALCULATION_DISABLE;
  hspi2.Init.CRCPolynomial = 10;
  if (HAL_SPI_Init(&hspi2) != HAL_OK)
  {
    Error_Handler();
  }

}

static void MX_TIM2_Init(void)
{

  TIM_ClockConfigTypeDef sClockSourceConfig = {0};
  TIM_MasterConfigTypeDef sMasterConfig = {0};

  htim2.Instance = TIM2;
  htim2.Init.Prescaler = 84-1;
  htim2.Init.CounterMode = TIM_COUNTERMODE_UP;
  htim2.Init.Period = 100000-1;
  htim2.Init.ClockDivision = TIM_CLOCKDIVISION_DIV1;
  htim2.Init.AutoReloadPreload = TIM_AUTORELOAD_PRELOAD_DISABLE;
  if (HAL_TIM_Base_Init(&htim2) != HAL_OK)
  {
    Error_Handler();
  }
  sClockSourceConfig.ClockSource = TIM_CLOCKSOURCE_INTERNAL;
  if (HAL_TIM_ConfigClockSource(&htim2, &sClockSourceConfig) != HAL_OK)
  {
    Error_Handler();
  }
  sMasterConfig.MasterOutputTrigger = TIM_TRGO_RESET;
  sMasterConfig.MasterSlaveMode = TIM_MASTERSLAVEMODE_DISABLE;
  if (HAL_TIMEx_MasterConfigSynchronization(&htim2, &sMasterConfig) != HAL_OK)
  {
    Error_Handler();
  }

}

static void MX_TIM3_Init(void)
{

  TIM_ClockConfigTypeDef sClockSourceConfig = {0};
  TIM_MasterConfigTypeDef sMasterConfig = {0};

  htim3.Instance = TIM3;
  htim3.Init.Prescaler = 167;
  htim3.Init.CounterMode = TIM_COUNTERMODE_UP;
  htim3.Init.Period = 49999;
  htim3.Init.ClockDivision = TIM_CLOCKDIVISION_DIV1;
  htim3.Init.AutoReloadPreload = TIM_AUTORELOAD_PRELOAD_ENABLE;
  if (HAL_TIM_Base_Init(&htim3) != HAL_OK)
  {
    Error_Handler();
  }
  sClockSourceConfig.ClockSource = TIM_CLOCKSOURCE_INTERNAL;
  if (HAL_TIM_ConfigClockSource(&htim3, &sClockSourceConfig) != HAL_OK)
  {
    Error_Handler();
  }
  sMasterConfig.MasterOutputTrigger = TIM_TRGO_RESET;
  sMasterConfig.MasterSlaveMode = TIM_MASTERSLAVEMODE_DISABLE;
  if (HAL_TIMEx_MasterConfigSynchronization(&htim3, &sMasterConfig) != HAL_OK)
  {
    Error_Handler();
  }

}

static void MX_TIM4_Init(void)
{

  TIM_ClockConfigTypeDef sClockSourceConfig = {0};
  TIM_MasterConfigTypeDef sMasterConfig = {0};

  htim4.Instance = TIM4;
  htim4.Init.Prescaler = 20;
  htim4.Init.CounterMode = TIM_COUNTERMODE_UP;
  htim4.Init.Period = 59999;
  htim4.Init.ClockDivision = TIM_CLOCKDIVISION_DIV1;
  htim4.Init.AutoReloadPreload = TIM_AUTORELOAD_PRELOAD_ENABLE;
  if (HAL_TIM_Base_Init(&htim4) != HAL_OK)
  {
    Error_Handler();
  }
  sClockSourceConfig.ClockSource = TIM_CLOCKSOURCE_INTERNAL;
  if (HAL_TIM_ConfigClockSource(&htim4, &sClockSourceConfig) != HAL_OK)
  {
    Error_Handler();
  }
  sMasterConfig.MasterOutputTrigger = TIM_TRGO_RESET;
  sMasterConfig.MasterSlaveMode = TIM_MASTERSLAVEMODE_DISABLE;
  if (HAL_TIMEx_MasterConfigSynchronization(&htim4, &sMasterConfig) != HAL_OK)
  {
    Error_Handler();
  }

}

static void MX_UART5_Init(void)
{

  huart5.Instance = UART5;
  huart5.Init.BaudRate = 115200;
  huart5.Init.WordLength = UART_WORDLENGTH_8B;
  huart5.Init.StopBits = UART_STOPBITS_1;
  huart5.Init.Parity = UART_PARITY_NONE;
  huart5.Init.Mode = UART_MODE_TX_RX;
  huart5.Init.HwFlowCtl = UART_HWCONTROL_NONE;
  huart5.Init.OverSampling = UART_OVERSAMPLING_16;
  if (HAL_UART_Init(&huart5) != HAL_OK)
  {
    Error_Handler();
  }

}

static void MX_USART1_UART_Init(void)
{

  huart1.Instance = USART1;
  huart1.Init.BaudRate = 115200;
  huart1.Init.WordLength = UART_WORDLENGTH_8B;
  huart1.Init.StopBits = UART_STOPBITS_1;
  huart1.Init.Parity = UART_PARITY_NONE;
  huart1.Init.Mode = UART_MODE_TX_RX;
  huart1.Init.HwFlowCtl = UART_HWCONTROL_NONE;
  huart1.Init.OverSampling = UART_OVERSAMPLING_16;
  if (HAL_UART_Init(&huart1) != HAL_OK)
  {
    Error_Handler();
  }

}

static void MX_USART2_UART_Init(void)
{

  huart2.Instance = USART2;
  huart2.Init.BaudRate = 115200;
  huart2.Init.WordLength = UART_WORDLENGTH_8B;
  huart2.Init.StopBits = UART_STOPBITS_1;
  huart2.Init.Parity = UART_PARITY_NONE;
  huart2.Init.Mode = UART_MODE_TX_RX;
  huart2.Init.HwFlowCtl = UART_HWCONTROL_NONE;
  huart2.Init.OverSampling = UART_OVERSAMPLING_16;
  if (HAL_UART_Init(&huart2) != HAL_OK)
  {
    Error_Handler();
  }

}

static void MX_USART3_UART_Init(void)
{

  huart3.Instance = USART3;
  huart3.Init.BaudRate = 115200;
  huart3.Init.WordLength = UART_WORDLENGTH_8B;
  huart3.Init.StopBits = UART_STOPBITS_1;
  huart3.Init.Parity = UART_PARITY_NONE;
  huart3.Init.Mode = UART_MODE_TX_RX;
  huart3.Init.HwFlowCtl = UART_HWCONTROL_NONE;
  huart3.Init.OverSampling = UART_OVERSAMPLING_16;
  if (HAL_UART_Init(&huart3) != HAL_OK)
  {
    Error_Handler();
  }

}

static void MX_USART6_UART_Init(void)
{

  huart6.Instance = USART6;
  huart6.Init.BaudRate = 3000000;
  huart6.Init.WordLength = UART_WORDLENGTH_8B;
  huart6.Init.StopBits = UART_STOPBITS_1;
  huart6.Init.Parity = UART_PARITY_NONE;
  huart6.Init.Mode = UART_MODE_TX_RX;
  huart6.Init.HwFlowCtl = UART_HWCONTROL_NONE;
  huart6.Init.OverSampling = UART_OVERSAMPLING_16;
  if (HAL_UART_Init(&huart6) != HAL_OK)
  {
    Error_Handler();
  }

}

static void MX_DMA_Init(void)
{

  /* DMA controller clock enable */
  __HAL_RCC_DMA1_CLK_ENABLE();
  __HAL_RCC_DMA2_CLK_ENABLE();

  /* DMA interrupt init */
  /* DMA1_Stream0_IRQn interrupt configuration */
  HAL_NVIC_SetPriority(DMA1_Stream0_IRQn, 0, 0);
  HAL_NVIC_EnableIRQ(DMA1_Stream0_IRQn);
  /* DMA1_Stream3_IRQn interrupt configuration */
  HAL_NVIC_SetPriority(DMA1_Stream3_IRQn, 0, 0);
  HAL_NVIC_EnableIRQ(DMA1_Stream3_IRQn);
  /* DMA1_Stream5_IRQn interrupt configuration */
  HAL_NVIC_SetPriority(DMA1_Stream5_IRQn, 0, 0);
  HAL_NVIC_EnableIRQ(DMA1_Stream5_IRQn);
  /* DMA1_Stream6_IRQn interrupt configuration */
  HAL_NVIC_SetPriority(DMA1_Stream6_IRQn, 0, 0);
  HAL_NVIC_EnableIRQ(DMA1_Stream6_IRQn);
  /* DMA1_Stream7_IRQn interrupt configuration */
  HAL_NVIC_SetPriority(DMA1_Stream7_IRQn, 0, 0);
  HAL_NVIC_EnableIRQ(DMA1_Stream7_IRQn);
  /* DMA2_Stream2_IRQn interrupt configuration */
  HAL_NVIC_SetPriority(DMA2_Stream2_IRQn, 0, 0);
  HAL_NVIC_EnableIRQ(DMA2_Stream2_IRQn);
  /* DMA2_Stream7_IRQn interrupt configuration */
  HAL_NVIC_SetPriority(DMA2_Stream7_IRQn, 0, 0);
  HAL_NVIC_EnableIRQ(DMA2_Stream7_IRQn);

}

static void MX_GPIO_Init(void)
{
  GPIO_InitTypeDef GPIO_InitStruct = {0};

  /* GPIO Ports Clock Enable */
  __HAL_RCC_GPIOC_CLK_ENABLE();
  __HAL_RCC_GPIOH_CLK_ENABLE();
  __HAL_RCC_GPIOA_CLK_ENABLE();
  __HAL_RCC_GPIOB_CLK_ENABLE();
  __HAL_RCC_GPIOD_CLK_ENABLE();

  /*Configure GPIO pin Output Level */
  HAL_GPIO_WritePin(GPIOC, MRF_RESET_Pin|SPI2_CS_MRF_Pin, GPIO_PIN_RESET);

  /*Configure GPIO pin Output Level */
  HAL_GPIO_WritePin(RS485_DIR_GPIO_Port, RS485_DIR_Pin, GPIO_PIN_RESET);

  /*Configure GPIO pin Output Level */
  HAL_GPIO_WritePin(BNO080_RST_GPIO_Port, BNO080_RST_Pin, GPIO_PIN_RESET);

  /*Configure GPIO pin Output Level */
  HAL_GPIO_WritePin(GYRO_PS0_GPIO_Port, GYRO_PS0_Pin, GPIO_PIN_SET);

  /*Configure GPIO pin : B1_Pin */
  GPIO_InitStruct.Pin = B1_Pin;
  GPIO_InitStruct.Mode = GPIO_MODE_IT_FALLING;
  GPIO_InitStruct.Pull = GPIO_NOPULL;
  HAL_GPIO_Init(B1_GPIO_Port, &GPIO_InitStruct);

  /*Configure GPIO pins : MRF_RESET_Pin SPI2_CS_MRF_Pin GYRO_PS0_Pin */
  GPIO_InitStruct.Pin = MRF_RESET_Pin|SPI2_CS_MRF_Pin|GYRO_PS0_Pin;
  GPIO_InitStruct.Mode = GPIO_MODE_OUTPUT_PP;
  GPIO_InitStruct.Pull = GPIO_NOPULL;
  GPIO_InitStruct.Speed = GPIO_SPEED_FREQ_LOW;
  HAL_GPIO_Init(GPIOC, &GPIO_InitStruct);

  /*Configure GPIO pin : BNO080_INT_Pin */
  GPIO_InitStruct.Pin = BNO080_INT_Pin;
  GPIO_InitStruct.Mode = GPIO_MODE_IT_FALLING;
  GPIO_InitStruct.Pull = GPIO_PULLUP;
  HAL_GPIO_Init(BNO080_INT_GPIO_Port, &GPIO_InitStruct);

  /*Configure GPIO pin : RS485_DIR_Pin */
  GPIO_InitStruct.Pin = RS485_DIR_Pin;
  GPIO_InitStruct.Mode = GPIO_MODE_OUTPUT_PP;
  GPIO_InitStruct.Pull = GPIO_NOPULL;
  GPIO_InitStruct.Speed = GPIO_SPEED_FREQ_LOW;
  HAL_GPIO_Init(RS485_DIR_GPIO_Port, &GPIO_InitStruct);

  /*Configure GPIO pin : BNO080_RST_Pin */
  GPIO_InitStruct.Pin = BNO080_RST_Pin;
  GPIO_InitStruct.Mode = GPIO_MODE_OUTPUT_PP;
  GPIO_InitStruct.Pull = GPIO_NOPULL;
  GPIO_InitStruct.Speed = GPIO_SPEED_FREQ_LOW;
  HAL_GPIO_Init(BNO080_RST_GPIO_Port, &GPIO_InitStruct);

  /*Configure GPIO pin : MRF_INT_Pin */
  GPIO_InitStruct.Pin = MRF_INT_Pin;
  GPIO_InitStruct.Mode = GPIO_MODE_IT_RISING;
  GPIO_InitStruct.Pull = GPIO_NOPULL;
  HAL_GPIO_Init(MRF_INT_GPIO_Port, &GPIO_InitStruct);

  /* EXTI interrupt init*/
  HAL_NVIC_SetPriority(EXTI1_IRQn, 0, 0);
  HAL_NVIC_EnableIRQ(EXTI1_IRQn);

  HAL_NVIC_SetPriority(EXTI9_5_IRQn, 0, 0);
  HAL_NVIC_EnableIRQ(EXTI9_5_IRQn);

  HAL_NVIC_SetPriority(EXTI15_10_IRQn, 0, 0);
  HAL_NVIC_EnableIRQ(EXTI15_10_IRQn);

}

/* USER CODE BEGIN 4 */

void HAL_CAN_RxFifo0MsgPendingCallback(CAN_HandleTypeDef *hcan)
{
    HAL_StatusTypeDef status;
    status = HAL_CAN_GetRxMessage(hcan, CAN_RX_FIFO0, &pRxHeader, CAN_received_data);
    if (status != HAL_OK)
    {
        // Error reading the message
        return;
    }

    uint32_t extId = pRxHeader.ExtId;
    uint8_t type   = (extId >> 24) & 0x1F;   // bits28..24
    uint8_t motorID= (extId >> 8) & 0xFFFF;  // Correct: Extracts bits 23–8
				   // bits7..0

    // Check what type we received
    if (type == 2) {  // Feedback message from motor

           // Extract current angle from Bytes 0-1
           uint16_t angle_raw = (CAN_received_data[0] << 8) | CAN_received_data[1];
           float angle = ((float)angle_raw / 65535.0f) * (ANGLE_MAX - ANGLE_MIN) + ANGLE_MIN + M_PI_2 - 10*M_PI/180.0f;
           // Convert to degrees
           //angle = angle * 180.0f / 3.14159265359f;

           // Extract angular velocity from Bytes 2-3
           uint16_t velocity_raw = (CAN_received_data[2] << 8) | CAN_received_data[3];
           float velocity = ((float)velocity_raw / 65535.0f) * (-30.0f - 30.0f) + 30.0f; // -30 to 30 rad/s

           // Extract torque from Bytes 4-5
           uint16_t torque_raw = (CAN_received_data[4] << 8) | CAN_received_data[5];
           float torque = ((float)torque_raw / 65535.0f) * (-12.0f - 12.0f) + 12.0f; // -12Nm to 12Nm

           // Extract temperature from Bytes 6-7
           uint16_t temp_raw = (CAN_received_data[6] << 8) | CAN_received_data[7];
           float temperature = (float)temp_raw / 10.0f; // Temp in Celsius

           // Find matching motor in motorList and update its values
           for (int i = 0; i < MAX_MOTORS; i++) {
               if (CyberGearMotorList[i].motorID == motorID) {
            	   CyberGearMotorList[i].angle = angle;
            	   CyberGearMotorList[i].velocity = velocity;
            	   CyberGearMotorList[i].torque = torque;
            	   CyberGearMotorList[i].temperature = temperature;
            	   //CyberGearMotorList[i].errorFlag = false;
            	   CyberGearMotorList[i].update_flag = true;

                   break;  // No need to check further once a match is found
               }
           }
           // Call watchdog function
           //watchdog(&CyberGearMotorList, &DDSM115MotorList, &LegGeometryList, &sampleTime);

       }
    else if (type == 17){

    }
    else if (type == 21)
    {
        // This is typically the fault/error frame
        // Byte0..3 might be a fault code

        // Optionally parse the fault code in received_data[0..3]
        // For example:
        /*uint32_t fault = (CAN_received_data[0])
                       | (CAN_received_data[1] << 8)
                       | (CAN_received_data[2] << 16)
                       | (CAN_received_data[3] << 24);*/
    }
    else if (type == 0)
    {
        // Possibly a "Get Device ID" response
        // The data bytes may contain the 64-bit unique ID
    }
    else
    {
        // Some other type

    }
}

void HAL_UART_RxCpltCallback(UART_HandleTypeDef *huart)
{
	if(huart->Instance == USART2){

		if(uart2RxBuffer[0] == 0xAA && uart2RxBuffer[1] == 0x55)
		{
			// Copy from buffer into current command array
			memcpy(ddsm_NN_current_command, uart2RxBuffer + 2, 8);

			// Re-arm DMA
			HAL_UART_Receive_DMA(&huart2, uart2RxBuffer, UART2_RX_BUFFER_SIZE);
		}

	}
	if(huart->Instance == UART4){
		//HAL_UART_Transmit(&huart2, &RxSingleByte, 1, 10);

	}

	 if (huart->Instance == USART3) {
	        if (uart3_controller_index == 0) {
	            if (uart3_controller_byte == 0xAA) {
	                uart3_controller_buf[uart3_controller_index++] = uart3_controller_byte;
	            }
	            // Else ignore random bytes
	        } else {
	            uart3_controller_buf[uart3_controller_index++] = uart3_controller_byte;
	            if (uart3_controller_index >= UART3_CONTROLLER_PACKET_LEN) {
	                uart3_controller_index = 0;
	                uart3_controller_packet_ready = 1;
	            }
	        }
	        HAL_UART_Receive_IT(&huart3, &uart3_controller_byte, 1);  // Re-arm
	    }
}

void HAL_UARTEx_RxEventCallback(UART_HandleTypeDef *huart, uint16_t Size)
{
	   if (huart->Instance == UART5)
	    {
	        uint8_t motor_id = RS485_RxBuffer[0];

	        for (int i = 0; i < MAX_MOTORS_DDSM115; i++) {
	            if (DDSM115MotorList[i].motorID == motor_id) {
	            	update_ddsm115_state(&DDSM115MotorList[i], RS485_RxBuffer, 0.0505f);
	                break;
	            }
	        }

	        // Restart reception for next frame
	        HAL_UARTEx_ReceiveToIdle_IT(&huart5, RS485_RxBuffer, RS485_BUFFER_SIZE);
	    }
    // DEAD PATH: the ESP32 that sent this packet no longer exists and USART1
    // reception is never armed (see USER CODE BEGIN 2). The BNO08x is read
    // directly over I2C3 by IMU_UpdateFromBNO(). Kept for reference only - do
    // not re-arm USART1 without first removing the *_esp32 writes below, or it
    // will fight the I2C3 source.
    if (huart->Instance == USART1)
    {
        // Size = number of bytes received into uart1RxBuffer[]
        uint16_t bytes = Size;
        uint16_t idx   = 0;

        // Process as many full packets as we have
        while (idx + PACKET_SIZE <= bytes)
        {
            if (uart1RxBuffer[idx] == 0xAA)
            {
                // Sync on first packet only
                if (!uartSynced)
                {
                    uartSynced = true;
                    // shift this good packet to buffer start if desired:
                    memmove(uart1RxBuffer,
                            uart1RxBuffer + idx,
                            PACKET_SIZE);
                    idx = 0;       // start parsing from buffer[0]
                    bytes = PACKET_SIZE;
                }

                // Parse the six floats (little-endian) at idx+1..idx+24
                float *f   = (float*)(uart1RxBuffer + idx + 1);
                yaw_esp32   = f[0];
                pitch_esp32 = f[1];
                roll_esp32  = f[2];
                gx_esp32    = f[3];
                gy_esp32    = f[4];
                gz_esp32    = f[5];

                // Advance past this packet
                idx += PACKET_SIZE;
            }
            else
            {
                // No SOF here, skip one byte
                idx++;
            }
        }

        // re-arm for next Idle
        HAL_UARTEx_ReceiveToIdle_IT(&huart1,
                                   uart1RxBuffer,
                                   UART1_RX_BUFFER_SIZE);
    }

}

void HAL_TIM_PeriodElapsedCallback(TIM_HandleTypeDef *htim)
{
	if (htim->Instance == TIM3)
	{
		// Every 10ms (100Hz)
		// Set the flag for CAN transmission
		//isCANReady = true;
	}
	if (htim->Instance == TIM4)
	{
		isDDSM115Ready = true;
		isCYBERGEARReady = true;
		isTELEMETRYReady = true;

	}

	if (htim->Instance == TIM2) {
		sendUart2Data = 1;
		//HAL_GPIO_TogglePin(GPIOA, LED_BUILTIN_Pin);  // ← visible blink
	}

}

/**
  * @brief Updates continuous base ANGLE (phi) and ANGULAR VELOCITY (phi_dot)
  *        AND linear position (x) and linear velocity (x_dot) based on DDSM115 feedback.
  *        Handles position wrap-around. Only processes data from motor 0x10.
  * @param Buffer: Pointer to the received RS485 data buffer.
  * @param current_phi_rad: Pointer to global variable storing continuous angular position (rad).
  * @param current_phi_dot_rad_s: Pointer to global variable storing angular velocity (rad/s).
  * @param current_x: Pointer to global variable storing linear position (m).
  * @param current_x_dot: Pointer to global variable storing linear velocity (m/s).
  * @retval None (Results are stored in the global variables via pointers).
  */

void HAL_UART_TxCpltCallback(UART_HandleTypeDef *huart)
{
    // Check if the callback is from our telemetry UART.
    if (huart->Instance == USART3) {
        // The transmission is complete, so we set the flag to true,
        // allowing the next call to Send_Telemetry() to proceed.
        Telemetry_UART_TxCpltCallback(huart);
    }
}

// ===== ANN INIT =====
void ANN_Init(void)
{
    stai_ptr act_addr[] = { (stai_ptr)ann_activations };
    stai_return_code err = stai_runtime_init();
    if (err != STAI_SUCCESS) {
        Error_Handler();
    }

    err = user_stai_network_init(ann_network_context);
    if (err != STAI_SUCCESS) {
        Error_Handler();
    }

    err = stai_network_set_activations(ann_network_context, act_addr, STAI_NETWORK_ACTIVATIONS_NUM);
    if (err != STAI_SUCCESS) {
        Error_Handler();
    }

    err = stai_network_set_inputs(ann_network_context, ann_input, STAI_NETWORK_IN_NUM);
    if (err != STAI_SUCCESS) {
        Error_Handler();
    }

    err = stai_network_set_outputs(ann_network_context, ann_output, STAI_NETWORK_OUT_NUM);
    if (err != STAI_SUCCESS) {
        Error_Handler();
    }
}

// ===== ANN INFERENCE =====
void ANN_Run(void)
{
    static bool refs_valid = false;
    static float phi_left_ref_nn = 0.0f;
    static float phi_right_ref_nn = 0.0f;
    static float yaw_ref_nn_rad = 0.0f;

    if (isFallen() && !isStartupStrategy) {
        refs_valid = false;
        prev_action_left = 0.0f;
        prev_action_right = 0.0f;
        ddsm_NN_current_command[0] = 0.0f;
        ddsm_NN_current_command[1] = 0.0f;
        return;
    }

    float phi_left_nn = WHEEL_POS_SIGN_LEFT * DDSM115MotorList[0].phi_rad;
    float phi_right_nn = WHEEL_POS_SIGN_RIGHT * DDSM115MotorList[1].phi_rad;
    float omega_left_nn = WHEEL_VEL_SIGN_LEFT * DDSM115MotorList[0].phi_dot_rad_s;
    float omega_right_nn = WHEEL_VEL_SIGN_RIGHT * DDSM115MotorList[1].phi_dot_rad_s;
    float yaw_nn_rad = YAW_SIGN * yaw_esp32;

    if (!refs_valid) {
        phi_left_ref_nn = phi_left_nn;
        phi_right_ref_nn = phi_right_nn;
        yaw_ref_nn_rad = yaw_nn_rad;
        refs_valid = true;
    }

    float s_left_m = WHEEL_RADIUS_R * (phi_left_nn - phi_left_ref_nn);
    float s_right_m = WHEEL_RADIUS_R * (phi_right_nn - phi_right_ref_nn);
    float v_left_mps = WHEEL_RADIUS_R * omega_left_nn;
    float v_right_mps = WHEEL_RADIUS_R * omega_right_nn;

    float x_rel_m = 0.5f * (s_left_m + s_right_m);
    float x_dot_mps = 0.5f * (v_left_mps + v_right_mps);
    float theta_rad = PITCH_SIGN * roll_esp32;
    float theta_dot_radps = PITCH_RATE_SIGN * gx_esp32;
    float yaw_error_rad = wrap_pi(yaw_nn_rad - yaw_ref_nn_rad);
    float yaw_rate_radps = YAW_RATE_SIGN * gz_esp32;

    // Current policy input: normalized obs[8].
    ann_in_data[0] = x_rel_m / 1.0f;
    ann_in_data[1] = x_dot_mps / 1.0f;
    ann_in_data[2] = theta_rad / 0.43633231f;
    ann_in_data[3] = theta_dot_radps / 4.0f;
    ann_in_data[4] = yaw_error_rad / 3.14159265f;
    ann_in_data[5] = yaw_rate_radps / 4.0f;
    ann_in_data[6] = prev_action_left / 2.0f;
    ann_in_data[7] = prev_action_right / 2.0f;

    for (uint32_t i = 0; i < STAI_NETWORK_IN_1_SIZE; i++) {
        if (!isfinite(ann_in_data[i])) {
            ann_in_data[i] = 0.0f;
        } else if (ann_in_data[i] > 10.0f) {
            ann_in_data[i] = 10.0f;
        } else if (ann_in_data[i] < -10.0f) {
            ann_in_data[i] = -10.0f;
        }
    }

    if (stai_network_run(ann_network_context, STAI_MODE_SYNC) != STAI_SUCCESS) {
        ddsm_NN_current_command[0] = 0.0f;
        ddsm_NN_current_command[1] = 0.0f;
        return;
    }

    float left_nn_current_A = ann_out_data[0];
    float right_nn_current_A = ann_out_data[1];

    if (!isfinite(left_nn_current_A) || !isfinite(right_nn_current_A)) {
        ddsm_NN_current_command[0] = 0.0f;
        ddsm_NN_current_command[1] = 0.0f;
        return;
    }

    prev_action_left = left_nn_current_A;
    prev_action_right = right_nn_current_A;

    ddsm_NN_current_command[0] = clamp_float(DDSM_CURRENT_SIGN_LEFT * left_nn_current_A,
                                             -STM32_TEST_CURRENT_LIMIT_A,
                                             STM32_TEST_CURRENT_LIMIT_A);
    ddsm_NN_current_command[1] = clamp_float(DDSM_CURRENT_SIGN_RIGHT * right_nn_current_A,
                                             -STM32_TEST_CURRENT_LIMIT_A,
                                             STM32_TEST_CURRENT_LIMIT_A);
    //ddsm_NN_current_command[0] = 0.0f;
    //ddsm_NN_current_command[1] = 0.0f;

}

static float clamp_float(float value, float min_value, float max_value)
{
    if (value < min_value) {
        return min_value;
    }
    if (value > max_value) {
        return max_value;
    }
    return value;
}

static float wrap_pi(float angle_rad)
{
    while (angle_rad > 3.14159265f) {
        angle_rad -= 6.28318531f;
    }
    while (angle_rad < -3.14159265f) {
        angle_rad += 6.28318531f;
    }
    return angle_rad;
}

// Updates all MET_* bench-metric variables from the current cycle's sensor/command
// values. Call once per 15ms control tick. See the MET_ globals above for what each
// one means and which metrics_per_run_template.csv column it maps to.
static void MET_Update(void)
{
    static bool  running         = false; // true once MET_reset has fired at least once
    static bool  have_init_theta = false;
    static float sum_theta_sq    = 0.0f;
    static float sum_I_sq        = 0.0f;
    static uint32_t sample_count = 0;
    static float x_ref_m         = 0.0f;
    static bool  disturbed       = false;
    static bool  recovered       = false;
    static float settle_timer_s  = 0.0f;

    if (MET_reset) {
        MET_reset = 0;

        have_init_theta = false;
        sum_theta_sq    = 0.0f;
        sum_I_sq        = 0.0f;
        sample_count    = 0;
        disturbed       = false;
        recovered       = false;
        settle_timer_s  = 0.0f;
        x_ref_m = WHEEL_RADIUS_R * 0.5f *
                  (WHEEL_POS_SIGN_LEFT  * DDSM115MotorList[0].phi_rad +
                   WHEEL_POS_SIGN_RIGHT * DDSM115MotorList[1].phi_rad);

        MET_theta_init_deg    = 0.0f;
        MET_theta_max_abs_deg = 0.0f;
        MET_theta_rms_deg     = 0.0f;
        MET_I_rms_A           = 0.0f;
        MET_t_rec_s           = 0.0f;
        MET_x_final_m         = 0.0f;
        MET_run_time_s        = 0.0f;

        running = true;
    }

    if (!running) {
        return; // wait for the first MET_reset before accumulating anything
    }

    float theta_deg = (PITCH_SIGN * roll_esp32) * MET_RAD2DEG;
    float abs_theta_deg = fabsf(theta_deg);
    MET_theta_deg = theta_deg;

    if (!have_init_theta) {
        MET_theta_init_deg = theta_deg;
        have_init_theta = true;
    }

    if (abs_theta_deg > MET_theta_max_abs_deg) {
        MET_theta_max_abs_deg = abs_theta_deg;
    }

    float x_m = WHEEL_RADIUS_R * 0.5f *
                (WHEEL_POS_SIGN_LEFT  * DDSM115MotorList[0].phi_rad +
                 WHEEL_POS_SIGN_RIGHT * DDSM115MotorList[1].phi_rad) - x_ref_m;
    MET_x_final_m = x_m;

    float i_avg_A = 0.5f * (fabsf(ddsm_NN_current_command[0]) + fabsf(ddsm_NN_current_command[1]));

    sample_count++;
    sum_theta_sq += theta_deg * theta_deg;
    sum_I_sq     += i_avg_A * i_avg_A;
    MET_theta_rms_deg = sqrtf(sum_theta_sq / (float)sample_count);
    MET_I_rms_A       = sqrtf(sum_I_sq     / (float)sample_count);

    MET_run_time_s += MET_SAMPLE_DT_S;

    // Recovery time: latch the elapsed time once |theta| has gone above the
    // "disturbed" threshold and then stayed below the (lower) "settled"
    // threshold continuously for MET_SETTLE_HOLD_S. Stays at 0 if the run
    // never leaves the disturbed threshold (e.g. undisturbed_balance).
    if (!recovered) {
        if (abs_theta_deg > MET_THETA_DISTURBED_DEG) {
            disturbed = true;
            settle_timer_s = 0.0f;
        }
        if (disturbed) {
            MET_t_rec_s = MET_run_time_s;
            if (abs_theta_deg < MET_THETA_SETTLED_DEG) {
                settle_timer_s += MET_SAMPLE_DT_S;
                if (settle_timer_s >= MET_SETTLE_HOLD_S) {
                    recovered = true; // MET_t_rec_s is now frozen
                }
            } else {
                settle_timer_s = 0.0f;
            }
        }
    }
}

// Updates all LOG_* per-tick telemetry variables. Call once per 15ms control tick,
// after ANN_Run() so ann_in_data/ann_out_data/ddsm_NN_current_command reflect this
// cycle's values. See the LOG_ globals above for the timeseries_log_template.csv
// column mapping.
static void LOG_Update(void)
{
    LOG_theta_deg = (PITCH_SIGN * roll_esp32) * MET_RAD2DEG;

    for (int i = 0; i < 8; i++) {
        LOG_obs[i] = ann_in_data[i];
    }

    LOG_action_L = ann_out_data[0];
    LOG_action_R = ann_out_data[1];

    LOG_I_L_cmd_A = ddsm_NN_current_command[0];
    LOG_I_R_cmd_A = ddsm_NN_current_command[1];

    // No current feedback from the DDSM115 drives - mirror the commanded value.
    LOG_I_L_meas_A = ddsm_NN_current_command[0];
    LOG_I_R_meas_A = ddsm_NN_current_command[1];
}

// Fills the legacy *_esp32 orientation globals from the directly-wired BNO08x,
// so every existing consumer (ANN_Run, MET_Update, LOG_Update, isFallen) keeps
// working unchanged. Call once per main-loop pass, after BNO08x_Service().
// See the "BNO08x mount mapping" block near PITCH_SIGN for why each of these is
// a straight assignment and not a negation.
static void IMU_UpdateFromBNO(void)
{
    // Leave the last good values in place until the sensor has produced its
    // first gravity/gyro/rotation report, so nothing downstream sees garbage.
    if (!bno_data_valid)
        return;

    // Balance axis. The old ESP32 packet called this "roll"; the training
    // contract calls the same quantity "pitch" (STM32_DEPLOYMENT.md: pitch
    // reads body-frame gravity Y). Same physical angle, same sign - only the
    // name changed. theta_rad = PITCH_SIGN * roll_esp32 downstream.
    roll_esp32  = atan2f(bno_gravity_y, -bno_gravity_z);

    // d(roll_esp32)/dt. Negated because atan2(g_y,-g_z) decreases as the
    // right-handed rotation about sensor X increases.
    gx_esp32    = -bno_gx;

    // Yaw angle and yaw rate. Both must live in the same frame or the policy
    // gets an angle and a rate that disagree; YAW_SIGN and YAW_RATE_SIGN
    // downstream are unchanged.
    //
    // bno_yaw_rad comes from the game-rotation quaternion, i.e. the BNO's
    // gravity-aligned WORLD frame. Raw bno_gz is BODY-frame gyro Z and on this
    // mounting has the opposite sense, so it cannot be used here (measured:
    // yaw_rate = -0.87 * d(yaw_err)/dt, corr -0.90, against +0.6..+0.9 in the
    // ERK runs). Rotate the complete gyro vector into world Z instead, which is
    // also what the training contract specifies (root_ang_vel_w[:, 2]) and what
    // TwoWheeledRobotEmbeddedCore's StateEstimator computes.
    float qw = bno_qw, qx = bno_qx, qy = bno_qy, qz = bno_qz;
    float q_norm_sq = qw*qw + qx*qx + qy*qy + qz*qz;
    float yaw_rate_world;
    if (q_norm_sq > 1.0e-8f) {
        float inv_q_norm = 1.0f / sqrtf(q_norm_sq);
        qw *= inv_q_norm; qx *= inv_q_norm; qy *= inv_q_norm; qz *= inv_q_norm;
        float r20 = 2.0f * (qx*qz - qw*qy);
        float r21 = 2.0f * (qy*qz + qw*qx);
        float r22 = 1.0f - 2.0f * (qx*qx + qy*qy);
        yaw_rate_world = r20*bno_gx + r21*bno_gy + r22*bno_gz;
    } else {
        yaw_rate_world = bno_gz;
    }

    yaw_esp32   = YAW_MOUNT_SIGN * bno_yaw_rad;
    gz_esp32    = YAW_MOUNT_SIGN * yaw_rate_world;

    // Not used by the policy or the metrics - kept current only so the
    // diagnostic sprintf() further up still prints something meaningful.
    pitch_esp32 = atan2f(bno_gravity_x, -bno_gravity_z);
    gy_esp32    = bno_gy;
}

// EXTI line 1 is the BNO08x data-ready INT (PA1). stm32f4xx_it.c's
// EXTI1_IRQHandler already calls HAL_GPIO_EXTI_IRQHandler(BNO080_INT_Pin);
// this is the HAL's weak callback it dispatches to.
void HAL_GPIO_EXTI_Callback(uint16_t GPIO_Pin)
{
    if (GPIO_Pin == BNO080_INT_Pin) {
        BNO08x_EXTI_Callback(GPIO_Pin);
    }
}

/* USER CODE END 4 */

void Error_Handler(void)
{
  __disable_irq();
  while (1)
  {
  }
}
